# NAVSS0_UDMASS_INTA_0_UDMASS_INTA0_CFG_L2G register map
Vendor: Texas Instruments
Peripheral module from a debugger description file (folder J7_AHP).
Registers are 64-bit, read-write, reset 0xFFFF unless marked. A register's access mark holds for its fields unless they carry their own. Offsets are as the file gives them; lines under a group give offsets from that group; [hi:lo] are bit positions; {n}, {i} and the like mark numbered series; 'fields as' and 'values as' point back to an identical list; <NAME> marks a mode.

## NAVSS0_UDMASS_INTA_0_UDMASS_INTA0_CFG_L2G
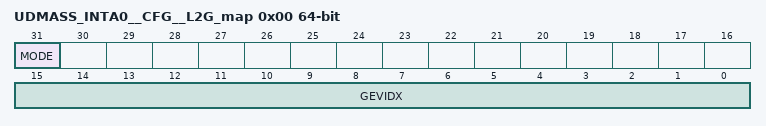
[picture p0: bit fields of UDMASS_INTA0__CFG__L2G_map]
0x00 UDMASS_INTA0__CFG__L2G_map
  [31] MODE — Local event detection mode. This field is set to 0 for pulsed events, and to 1 for rising edge eventss
  [15:0] GEVIDX — Global event index. This field specifies the index of the outgoing global event. Set to 0xFFFF to disable.
